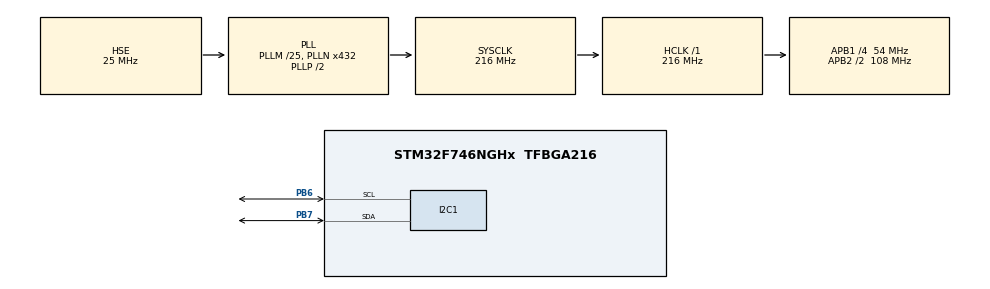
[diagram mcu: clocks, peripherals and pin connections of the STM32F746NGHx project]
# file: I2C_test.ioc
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I2C1.Timing=0x20404768
Mcu.Family=STM32F7
Mcu.Name=STM32F746NGHx
Mcu.Package=TFBGA216
NVIC.PriorityGroup=NVIC_PRIORITYGROUP_4
PB6.Mode=I2C
PB6.Signal=I2C1_SCL
PB7.Mode=I2C
PB7.Signal=I2C1_SDA
PH0/OSC_IN.Mode=HSE-External-Oscillator
PH0/OSC_IN.Signal=RCC_OSC_IN
PH1/OSC_OUT.Mode=HSE-External-Oscillator
PH1/OSC_OUT.Signal=RCC_OSC_OUT
ProjectManager.HeapSize=0x200
ProjectManager.StackSize=0x400
ProjectManager.TargetToolchain=STM32CubeIDE
RCC.AHBFreq_Value=216000000
RCC.APB1CLKDivider=RCC_HCLK_DIV4
RCC.APB1Freq_Value=54000000
RCC.APB1TimFreq_Value=108000000
RCC.APB2CLKDivider=RCC_HCLK_DIV2
RCC.APB2Freq_Value=108000000
RCC.APB2TimFreq_Value=216000000
RCC.CortexFreq_Value=216000000
RCC.HCLKFreq_Value=216000000
RCC.HSE_VALUE=25000000
RCC.HSI_VALUE=16000000
RCC.LSE_VALUE=32768
RCC.PLLM=25
RCC.PLLN=432
RCC.PLLSourceVirtual=RCC_PLLSOURCE_HSE
RCC.SYSCLKFreq_VALUE=216000000
RCC.SYSCLKSource=RCC_SYSCLKSOURCE_PLLCLK
RCC.USBFreq_Value=216000000
RCC.VCOOutputFreq_Value=432000000
board=STM32F746G-DISCO

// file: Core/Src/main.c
/* USER CODE BEGIN Header */
/**
  ******************************************************************************
  * @file           : main.c
  * @brief          : Main program body
  ******************************************************************************
  * @attention
  *
  * Copyright (c) 2025 STMicroelectronics.
  * All rights reserved.
  *
  * This software is licensed under terms that can be found in the LICENSE file
  * in the root directory of this software component.
  * If no LICENSE file comes with this software, it is provided AS-IS.
  *
  ******************************************************************************
  */
/* USER CODE END Header */
#include "main.h"

/* USER CODE BEGIN Includes */

//Based on STM32Cube HAL functions, I2C data transfer can be performed in 3 modes: Blocking Mode, Interrupt Mode or DMA Mode
/*    Blocking Mode:

The communication is performed in polling mode. The status of all data processing is returned by the same function after finishing transfer.

        HAL_I2C_Master_Transmit()
        HAL_I2C_Master_Receive()
        HAL_I2C_Slave_Transmit()
        HAL_I2C_Slave_Receive()
        HAL_I2C_Mem_Write()
        HAL_I2C_Mem_Read()

    Non-blocking modes

The communication is performed using Interrupts or DMA. These functions return the status of the transfer startup.
The end of the data processing will be indicated through the dedicated I2C IRQ when using Interrupt mode or the DMA IRQ when using DMA mode.

        Interrupt Mode:

        HAL_I2C_Master_Transmit_IT()
        HAL_I2C_Master_Receive_IT()
        HAL_I2C_Slave_Transmit_IT()
        HAL_I2C_Slave_Receive_IT()
        HAL_I2C_Mem_Write_IT()
        HAL_I2C_Mem_Read_IT()

        DMA Mode:

        HAL_I2C_Master_Transmit_DMA()
        HAL_I2C_Master_Receive_DMA()
        HAL_I2C_Slave_Transmit_DMA()
        HAL_I2C_Slave_Receive_DMA()
        HAL_I2C_Mem_Write_DMA()
        HAL_I2C_Mem_Read_DMA()*/

/* USER CODE END Includes */

I2C_HandleTypeDef hi2c1;

/* USER CODE BEGIN PV */
uint8_t write_data[]= {'H', 'I'};
uint8_t read_data[2];
/* USER CODE END PV */

void SystemClock_Config(void);
static void MX_GPIO_Init(void);
static void MX_I2C1_Init(void);

int main(void)
{

  /* MCU Configuration--------------------------------------------------------*/

  /* Reset of all peripherals, Initializes the Flash interface and the Systick. */
  HAL_Init();

  /* Configure the system clock */
  SystemClock_Config();

  /* Initialize all configured peripherals */
  MX_GPIO_Init();
  MX_I2C1_Init();
  /* USER CODE BEGIN 2 */
uint8_t tx_buffer[3];
tx_buffer[0]= 0x00; //EEPROM Memory address
tx_buffer[1]= write_data[0]; // 'H'
tx_buffer[2]= write_data[1]; // 'i'
/*Search for why HAL_I2C_Master_Transmit not used for EEPROMs*/
if (HAL_I2C_Master_Transmit(&hi2c1, 0xA0, tx_buffer, 3, HAL_MAX_DELAY) != HAL_OK) //0xA0= (0x50 << 1)
  {
      Error_Handler();
  }
  HAL_Delay(5);  // Wait for EEPROM write cycle

  // Read back 2 bytes from EEPROM address 0x00
  uint8_t mem_address = 0x00;
  if (HAL_I2C_Master_Transmit(&hi2c1, 0xA0, &mem_address, 1, HAL_MAX_DELAY) != HAL_OK)
  {
      Error_Handler();
  }
  if (HAL_I2C_Master_Receive(&hi2c1, 0xA0, read_data, 2, HAL_MAX_DELAY) != HAL_OK)
  {
      Error_Handler();
  }
  /* USER CODE END 2 */

  /* Infinite loop */
  while (1)
  {
	  HAL_Delay(1000);
  }
}

void SystemClock_Config(void)
{
  RCC_OscInitTypeDef RCC_OscInitStruct = {0};
  RCC_ClkInitTypeDef RCC_ClkInitStruct = {0};

  /** Configure the main internal regulator output voltage
  */
  __HAL_RCC_PWR_CLK_ENABLE();
  __HAL_PWR_VOLTAGESCALING_CONFIG(PWR_REGULATOR_VOLTAGE_SCALE1);

  /** Initializes the RCC Oscillators according to the specified parameters
  * in the RCC_OscInitTypeDef structure.
  */
  RCC_OscInitStruct.OscillatorType = RCC_OSCILLATORTYPE_HSE;
  RCC_OscInitStruct.HSEState = RCC_HSE_ON;
  RCC_OscInitStruct.PLL.PLLState = RCC_PLL_ON;
  RCC_OscInitStruct.PLL.PLLSource = RCC_PLLSOURCE_HSE;
  RCC_OscInitStruct.PLL.PLLM = 25;
  RCC_OscInitStruct.PLL.PLLN = 432;
  RCC_OscInitStruct.PLL.PLLP = RCC_PLLP_DIV2;
  RCC_OscInitStruct.PLL.PLLQ = 2;
  if (HAL_RCC_OscConfig(&RCC_OscInitStruct) != HAL_OK)
  {
    Error_Handler();
  }

  /** Activate the Over-Drive mode
  */
  if (HAL_PWREx_EnableOverDrive() != HAL_OK)
  {
    Error_Handler();
  }

  /** Initializes the CPU, AHB and APB buses clocks
  */
  RCC_ClkInitStruct.ClockType = RCC_CLOCKTYPE_HCLK|RCC_CLOCKTYPE_SYSCLK
                              |RCC_CLOCKTYPE_PCLK1|RCC_CLOCKTYPE_PCLK2;
  RCC_ClkInitStruct.SYSCLKSource = RCC_SYSCLKSOURCE_PLLCLK;
  RCC_ClkInitStruct.AHBCLKDivider = RCC_SYSCLK_DIV1;
  RCC_ClkInitStruct.APB1CLKDivider = RCC_HCLK_DIV4;
  RCC_ClkInitStruct.APB2CLKDivider = RCC_HCLK_DIV2;

  if (HAL_RCC_ClockConfig(&RCC_ClkInitStruct, FLASH_LATENCY_7) != HAL_OK)
  {
    Error_Handler();
  }
}

static void MX_I2C1_Init(void)
{

  hi2c1.Instance = I2C1;
  hi2c1.Init.Timing = 0x20404768;
  hi2c1.Init.OwnAddress1 = 0;
  hi2c1.Init.AddressingMode = I2C_ADDRESSINGMODE_7BIT;
  hi2c1.Init.DualAddressMode = I2C_DUALADDRESS_DISABLE;
  hi2c1.Init.OwnAddress2 = 0;
  hi2c1.Init.OwnAddress2Masks = I2C_OA2_NOMASK;
  hi2c1.Init.GeneralCallMode = I2C_GENERALCALL_DISABLE;
  hi2c1.Init.NoStretchMode = I2C_NOSTRETCH_DISABLE;
  if (HAL_I2C_Init(&hi2c1) != HAL_OK)
  {
    Error_Handler();
  }

  /** Configure Analogue filter
  */
  if (HAL_I2CEx_ConfigAnalogFilter(&hi2c1, I2C_ANALOGFILTER_ENABLE) != HAL_OK)
  {
    Error_Handler();
  }

  /** Configure Digital filter
  */
  if (HAL_I2CEx_ConfigDigitalFilter(&hi2c1, 0) != HAL_OK)
  {
    Error_Handler();
  }

}

static void MX_GPIO_Init(void)
{
  /* USER CODE BEGIN MX_GPIO_Init_1 */
	GPIO_InitTypeDef GPIO_InitStruct = {0};  // <-- Add this line

  /* USER CODE END MX_GPIO_Init_1 */

  /* GPIO Ports Clock Enable */
  __HAL_RCC_GPIOB_CLK_ENABLE();
  __HAL_RCC_GPIOH_CLK_ENABLE();

  /* USER CODE BEGIN MX_GPIO_Init_2 */
  GPIO_InitStruct.Pin = GPIO_PIN_6 | GPIO_PIN_7;
  GPIO_InitStruct.Mode = GPIO_MODE_AF_OD;
  GPIO_InitStruct.Pull = GPIO_PULLUP;
  GPIO_InitStruct.Speed = GPIO_SPEED_FREQ_VERY_HIGH;
  GPIO_InitStruct.Alternate = GPIO_AF4_I2C1;
  HAL_GPIO_Init(GPIOB, &GPIO_InitStruct);
}

  /* USER CODE END MX_GPIO_Init_2 */

void Error_Handler(void)
{
  __disable_irq();
  while (1)
  {
  }
}
